# UPD70F3508 register map
Vendor: Renesas; Series: V850E2/Px4; File version: 1.0
CPU: other r0p0, little endian, no MPU, FPU, 4 interrupt priority bits
Registers are 8-bit, read-write, reset 0x0 unless marked. A register's access mark holds for its fields unless they carry their own. Offsets are from the block's base; [hi:lo] are bit positions; {n}, {i} and the like mark numbered series.

## SGAC — Safety Guardian Checker register area
Base 0xFF83D000
0x00 SGACESET 32-bit wo — SGA checker error set trigger register
  [0] SGACEST — SGA error set trigger: 1=initiate active state of SGATERROUTZ (low)
0x04 SGACECLR 32-bit wo — SGA checker error clear trigger register
  [0] SGACECT — SGA error clear trigger: 1=initiate inactive state of SGATERROUTZ (high)
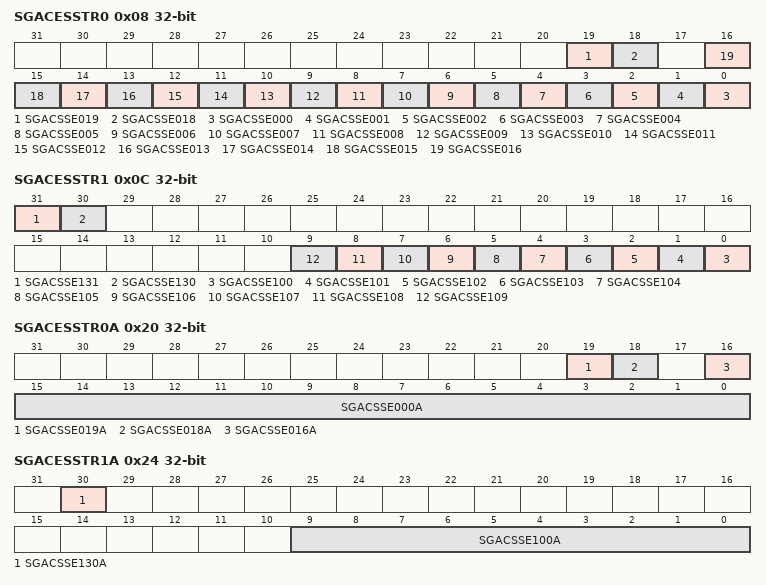
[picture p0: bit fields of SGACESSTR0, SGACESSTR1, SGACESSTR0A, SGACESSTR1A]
0x08 SGACESSTR0 32-bit ro — SGA checker error source status register 0
  [19] SGACSSE019 — SGATERRIN19 error status
  [18] SGACSSE018 — SGATERRIN18 error status
  [n] SGACSSE{n:03} (n=0..16) — SGATERRIN{n} error status
0x0C SGACESSTR1 32-bit ro — SGA checker error source status register 1
  [31] SGACSSE131 — Error output loop-back state (SGATERRLB): 0=low, 1=high
  [30] SGACSSE130 — SGAmESET write status (SGATERRSWS): 1=error set
  [n-100] SGACSSE{n} (n=100..109) — SGATERRIN{n-68} error status
0x10 SGACPCMD0 32-bit wo — SGA checker protection command register
  [7:0] SGAC0REG — Protection command [7:0] to enable writing to SGAC registers
0x20 SGACESSTR0A 32-bit ro — SGA checker error source status register 0A (majority A)
  [19] SGACSSE019A — SGATERRIN19 majority-A status
  [18] SGACSSE018A — SGATERRIN18 majority-A status
  [16] SGACSSE016A — SGATERRIN16 majority-A status
  [15:0] SGACSSE000A — SGATERRIN0-15 majority-A status [15:0]
0x24 SGACESSTR1A 32-bit ro — SGA checker error source status register 1A (majority A)
  [30] SGACSSE130A — Error set trigger state majority-A
  [9:0] SGACSSE100A — SGATERRIN32-41 majority-A status [9:0]
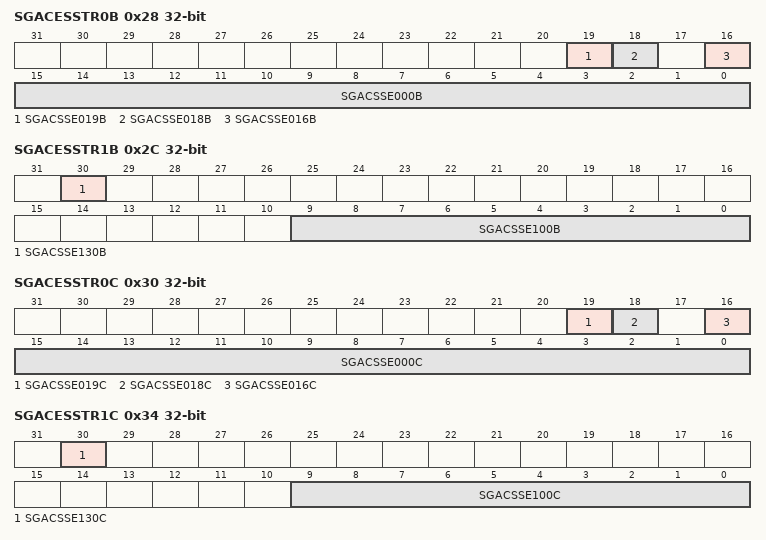
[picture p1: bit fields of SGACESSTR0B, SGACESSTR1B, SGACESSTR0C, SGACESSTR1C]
0x28 SGACESSTR0B 32-bit ro — SGA checker error source status register 0B (majority B)
  [19] SGACSSE019B — SGATERRIN19 majority-B status
  [18] SGACSSE018B — SGATERRIN18 majority-B status
  [16] SGACSSE016B — SGATERRIN16 majority-B status
  [15:0] SGACSSE000B — SGATERRIN0-15 majority-B status [15:0]
0x2C SGACESSTR1B 32-bit ro — SGA checker error source status register 1B (majority B)
  [30] SGACSSE130B — Error set trigger state majority-B
  [9:0] SGACSSE100B — SGATERRIN32-41 majority-B status [9:0]
0x30 SGACESSTR0C 32-bit ro — SGA checker error source status register 0C (majority C)
  [19] SGACSSE019C — SGATERRIN19 majority-C status
  [18] SGACSSE018C — SGATERRIN18 majority-C status
  [16] SGACSSE016C — SGATERRIN16 majority-C status
  [15:0] SGACSSE000C — SGATERRIN0-15 majority-C status [15:0]
0x34 SGACESSTR1C 32-bit ro — SGA checker error source status register 1C (majority C)
  [30] SGACSSE130C — Error set trigger state majority-C
  [9:0] SGACSSE100C — SGATERRIN32-41 majority-C status [9:0]

## SGA_COMMON — Safety Guardian common register area (accessed simultaneously by both master and checker)
Base 0xFF83E000
0x00 SGAEPCFG 32-bit — SGA error pulse configuration register
  [0] SGASL0 — Error output operation: 0=non-dynamic, 1=dynamic (toggles per SGATTIN)
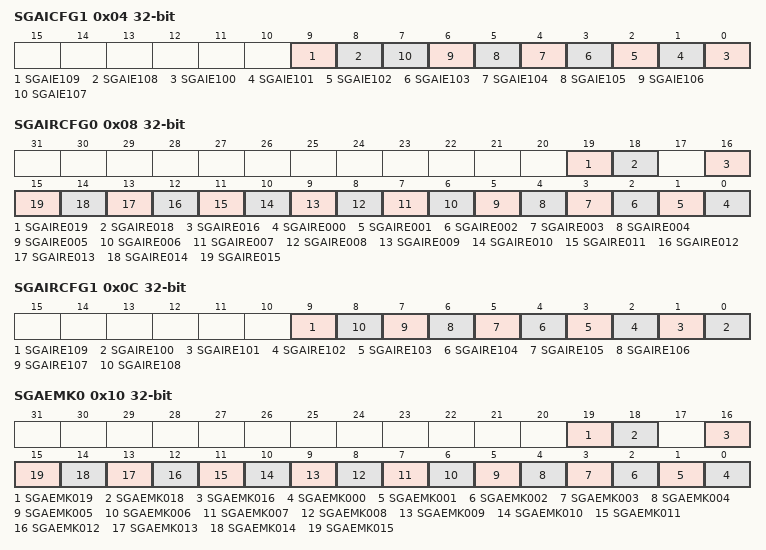
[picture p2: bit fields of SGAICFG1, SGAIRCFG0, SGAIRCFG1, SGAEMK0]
0x04 SGAICFG1 32-bit — SGA interrupt configuration register 1
  [9] SGAIE109 — SGATI interrupt enable for SGATERRIN41 (note: setting to 1 does not generate interrupt)
  [8] SGAIE108 — SGATI interrupt enable for SGATERRIN40: 0=disabled, 1=enabled
  [n-100] SGAIE{n} (n=100..107) — SGATI interrupt enable for SGATERRIN{n-68}
0x08 SGAIRCFG0 32-bit — SGA internal reset configuration register 0
  [19] SGAIRE019 — SGARES enable for SGATERRIN19: 0=disabled, 1=enabled
  [18] SGAIRE018 — SGARES enable for SGATERRIN18
  [16] SGAIRE016 — SGARES enable for SGATERRIN16 (not present on UPD70F3508/3509)
  [n] SGAIRE{n:03} (n=0..15) — SGARES enable for SGATERRIN{n}
0x0C SGAIRCFG1 32-bit — SGA internal reset configuration register 1
  [9] SGAIRE109 — SGARES enable for SGATERRIN41: 0=disabled, 1=enabled
  [n-100] SGAIRE{n} (n=100..108) — SGARES enable for SGATERRIN{n-68}
0x10 SGAEMK0 32-bit — SGA SGATERROUTZ mask register 0
  [19] SGAEMK019 — Mask SGATERRIN19 from SGATERROUTZ: 0=not masked, 1=masked
  [18] SGAEMK018 — Mask SGATERRIN18 from SGATERROUTZ
  [16] SGAEMK016 — Mask SGATERRIN16 from SGATERROUTZ (not present on UPD70F3508/3509)
  [n] SGAEMK{n:03} (n=0..15) — Mask SGATERRIN{n} from SGATERROUTZ
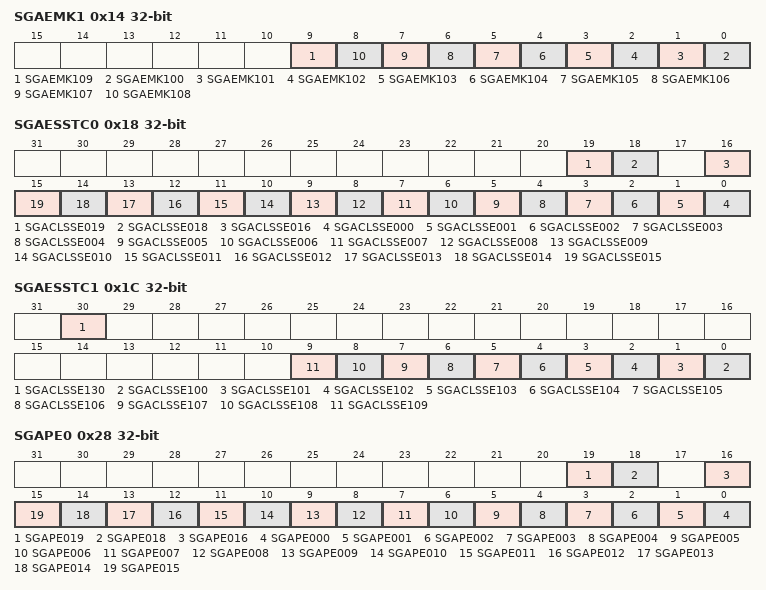
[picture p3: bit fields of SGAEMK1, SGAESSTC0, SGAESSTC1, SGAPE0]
0x14 SGAEMK1 32-bit — SGA SGATERROUTZ mask register 1
  [9] SGAEMK109 — Mask SGATERRIN41 (note: setting 1 does not mask SGATERRIN41): 0=not masked, 1=masked
  [n-100] SGAEMK{n} (n=100..108) — Mask SGATERRIN{n-68} from SGATERROUTZ
0x18 SGAESSTC0 32-bit wo — SGA error source status clear register 0
  [19] SGACLSSE019 — Clear SGAmESSTR0.SGASSE019: 1=clear
  [18] SGACLSSE018 — Clear SGAmESSTR0.SGASSE018: 1=clear
  [16] SGACLSSE016 — Clear SGAmESSTR0.SGASSE016: 1=clear (not present on UPD70F3508/3509)
  [n] SGACLSSE{n:03} (n=0..15) — Clear SGAmESSTR0.SGASSE{n:03}: 1=clear
0x1C SGAESSTC1 32-bit wo — SGA error source status clear register 1
  [30] SGACLSSE130 — Clear SGAmESSTR1.SGASSE130: 1=clear
  [n-100] SGACLSSE{n} (n=100..109) — Clear SGAmESSTR1.SGASSE{n}: 1=clear
0x20 SGAPCMD1 32-bit wo — SGA protection command register
  [7:0] SGA1REG — Protection command [7:0] to enable writing to SGA common registers
0x24 SGAPS 32-bit ro — SGA protection status register
  [0] SGAPRERR — Protected register write result: 0=success, 1=failed
0x28 SGAPE0 32-bit wo — SGA pseudo error trigger register 0
  [19] SGAPE019 — Pseudo error for SGATERRIN19: 1=inject
  [18] SGAPE018 — Pseudo error for SGATERRIN18: 1=inject
  [16] SGAPE016 — Pseudo error for SGATERRIN16 (not present on UPD70F3508/3509): 1=inject
  [n] SGAPE{n:03} (n=0..15) — Pseudo error for SGATERRIN{n}: 1=inject
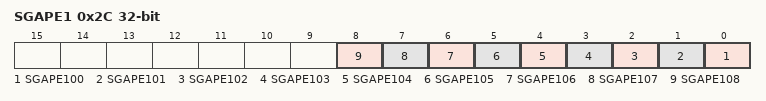
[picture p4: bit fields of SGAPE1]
0x2C SGAPE1 32-bit wo — SGA pseudo error trigger register 1
  [n-100] SGAPE{n} (n=100..108) — Pseudo error for SGATERRIN{n-68}: 1=inject
